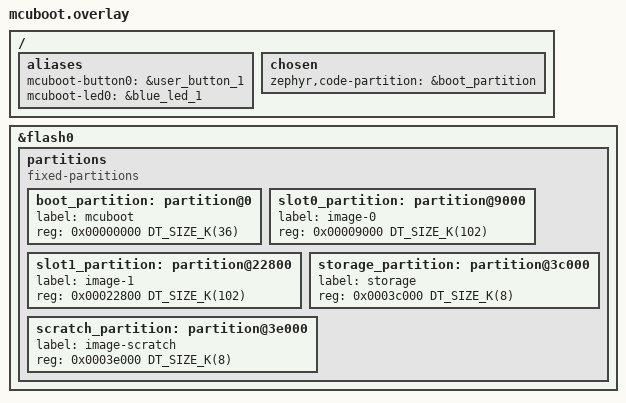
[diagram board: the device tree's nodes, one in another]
/{
    aliases{
        mcuboot-button0 = &user_button_1;
        mcuboot-led0 = &blue_led_1;
    };
    
    chosen {
        zephyr,code-partition = &boot_partition;
    };
};

/* 
 * Flash partition layout for STM32WL55JC (256KB total flash)
 * MCUboot bootloader starts at 0x08000000 (flash base address)
 * Layout: 36KB boot + 102KB slot0 + 102KB slot1 + 8KB storage + 8KB scratch = 256KB
 */
&flash0 {
    /* Delete existing partitions node to avoid conflicts */
    /delete-node/ partitions;
    
    partitions {
        compatible = "fixed-partitions";
        #address-cells = <1>;
        #size-cells = <1>;

        /* MCUboot bootloader - 36KB at base address (minimum required) */
        boot_partition: partition@0 {
            label = "mcuboot";
            reg = <0x00000000 DT_SIZE_K(36)>;
        };

        /* Primary application slot (slot0) - 102KB */
        slot0_partition: partition@9000 {
            label = "image-0";
            reg = <0x00009000 DT_SIZE_K(102)>;
        };

        /* Secondary application slot (slot1) - 102KB */
        slot1_partition: partition@22800 {
            label = "image-1";
            reg = <0x00022800 DT_SIZE_K(102)>;
        };

        /* Storage partition - 8KB */
        storage_partition: partition@3c000 {
            label = "storage";
            reg = <0x0003c000 DT_SIZE_K(8)>;
        };

        /* Scratch area for image swapping - 8KB */
        scratch_partition: partition@3e000 {
            label = "image-scratch";
            reg = <0x0003e000 DT_SIZE_K(8)>;
        };
    };
};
